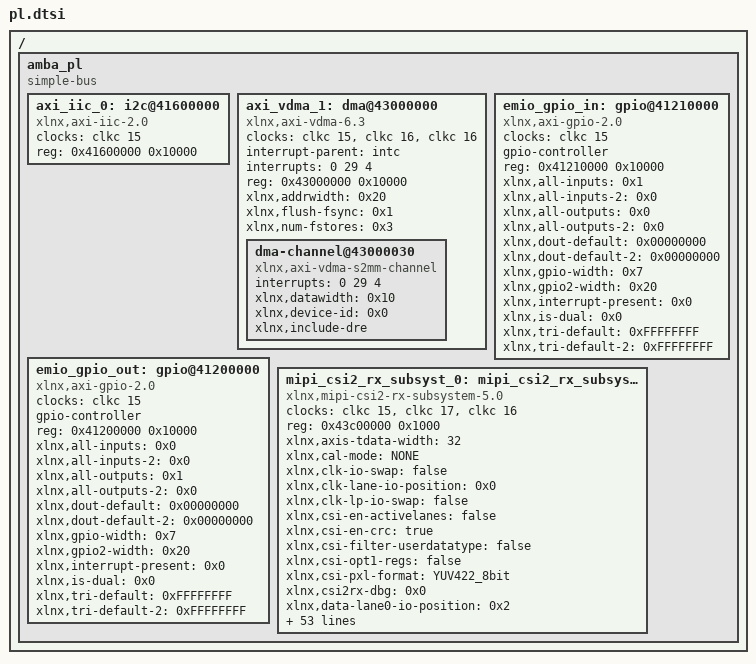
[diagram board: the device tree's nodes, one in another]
/*
 * CAUTION: This file is automatically generated by Xilinx.
 * Version:  
 * Today is: Sat Nov 14 14:24:52 2020
 */


/ {
	amba_pl: amba_pl {
		#address-cells = <1>;
		#size-cells = <1>;
		compatible = "simple-bus";
		ranges ;
		axi_iic_0: i2c@41600000 {
			#address-cells = <1>;
			#size-cells = <0>;
			clock-names = "s_axi_aclk";
			clocks = <&clkc 15>;
			compatible = "xlnx,axi-iic-2.0", "xlnx,xps-iic-2.00.a";
			reg = <0x41600000 0x10000>;
		};
		axi_vdma_1: dma@43000000 {
			#dma-cells = <1>;
			clock-names = "s_axi_lite_aclk", "m_axi_s2mm_aclk", "s_axis_s2mm_aclk";
			clocks = <&clkc 15>, <&clkc 16>, <&clkc 16>;
			compatible = "xlnx,axi-vdma-6.3", "xlnx,axi-vdma-1.00.a";
			interrupt-names = "s2mm_introut";
			interrupt-parent = <&intc>;
			interrupts = <0 29 4>;
			reg = <0x43000000 0x10000>;
			xlnx,addrwidth = <0x20>;
			xlnx,flush-fsync = <0x1>;
			xlnx,num-fstores = <0x3>;
			dma-channel@43000030 {
				compatible = "xlnx,axi-vdma-s2mm-channel";
				interrupts = <0 29 4>;
				xlnx,datawidth = <0x10>;
				xlnx,device-id = <0x0>;
				xlnx,include-dre ;
			};
		};
		emio_gpio_in: gpio@41210000 {
			#gpio-cells = <3>;
			clock-names = "s_axi_aclk";
			clocks = <&clkc 15>;
			compatible = "xlnx,axi-gpio-2.0", "xlnx,xps-gpio-1.00.a";
			gpio-controller ;
			reg = <0x41210000 0x10000>;
			xlnx,all-inputs = <0x1>;
			xlnx,all-inputs-2 = <0x0>;
			xlnx,all-outputs = <0x0>;
			xlnx,all-outputs-2 = <0x0>;
			xlnx,dout-default = <0x00000000>;
			xlnx,dout-default-2 = <0x00000000>;
			xlnx,gpio-width = <0x7>;
			xlnx,gpio2-width = <0x20>;
			xlnx,interrupt-present = <0x0>;
			xlnx,is-dual = <0x0>;
			xlnx,tri-default = <0xFFFFFFFF>;
			xlnx,tri-default-2 = <0xFFFFFFFF>;
		};
		emio_gpio_out: gpio@41200000 {
			#gpio-cells = <3>;
			clock-names = "s_axi_aclk";
			clocks = <&clkc 15>;
			compatible = "xlnx,axi-gpio-2.0", "xlnx,xps-gpio-1.00.a";
			gpio-controller ;
			reg = <0x41200000 0x10000>;
			xlnx,all-inputs = <0x0>;
			xlnx,all-inputs-2 = <0x0>;
			xlnx,all-outputs = <0x1>;
			xlnx,all-outputs-2 = <0x0>;
			xlnx,dout-default = <0x00000000>;
			xlnx,dout-default-2 = <0x00000000>;
			xlnx,gpio-width = <0x7>;
			xlnx,gpio2-width = <0x20>;
			xlnx,interrupt-present = <0x0>;
			xlnx,is-dual = <0x0>;
			xlnx,tri-default = <0xFFFFFFFF>;
			xlnx,tri-default-2 = <0xFFFFFFFF>;
		};
		mipi_csi2_rx_subsyst_0: mipi_csi2_rx_subsystem@43c00000 {
			clock-names = "lite_aclk", "dphy_clk_200M", "video_aclk";
			clocks = <&clkc 15>, <&clkc 17>, <&clkc 16>;
			compatible = "xlnx,mipi-csi2-rx-subsystem-5.0";
			reg = <0x43c00000 0x1000>;
			xlnx,axis-tdata-width = <32>;
			xlnx,cal-mode = "NONE";
			xlnx,clk-io-swap = "false";
			xlnx,clk-lane-io-position = <0x0>;
			xlnx,clk-lp-io-swap = "false";
			xlnx,csi-en-activelanes = "false";
			xlnx,csi-en-crc = "true";
			xlnx,csi-filter-userdatatype = "false";
			xlnx,csi-opt1-regs = "false";
			xlnx,csi-pxl-format = "YUV422_8bit";
			xlnx,csi2rx-dbg = <0x0>;
			xlnx,data-lane0-io-position = <0x2>;
			xlnx,data-lane1-io-position = <0x4>;
			xlnx,data-lane2-io-position = <0x6>;
			xlnx,data-lane3-io-position = <0x8>;
			xlnx,dl0-io-swap = "false";
			xlnx,dl0-lp-io-swap = "false";
			xlnx,dl1-io-swap = "false";
			xlnx,dl1-lp-io-swap = "false";
			xlnx,dl2-io-swap = "false";
			xlnx,dl2-lp-io-swap = "false";
			xlnx,dl3-io-swap = "false";
			xlnx,dl3-lp-io-swap = "false";
			xlnx,dphy-lanes = <0x4>;
			xlnx,dphy-mode = "SLAVE";
			xlnx,en-bg0-pin0 = "false";
			xlnx,en-bg0-pin6 = "false";
			xlnx,en-bg1-pin0 = "false";
			xlnx,en-bg1-pin6 = "false";
			xlnx,en-bg2-pin0 = "false";
			xlnx,en-bg2-pin6 = "false";
			xlnx,en-bg3-pin0 = "false";
			xlnx,en-bg3-pin6 = "false";
			xlnx,en-clk300m = "false";
			xlnx,en-cnts-byte-clk = "false";
			xlnx,en-csi-v2-0 = "false";
			xlnx,en-exdesigns = "false";
			xlnx,en-timeout-regs = "false";
			xlnx,en-vcx = "false";
			xlnx,esc-timeout = <0x6400>;
			xlnx,exdes-board = "ZCU102";
			xlnx,exdes-config = "MIPI_Video_Pipe_Camera_to_Display";
			xlnx,exdes-fmc = "LI-IMX274MIPI-FMC V1.0 Single Sensor";
			xlnx,fifo-rd-en-control = "true";
			xlnx,hs-line-rate = <0x320>;
			xlnx,hs-settle-ns = <0x93>;
			xlnx,hs-timeout = <0x10005>;
			xlnx,idly-group-name = "mipi_csi2rx_idly_group";
			xlnx,idly-tap = <0x1>;
			xlnx,init = <0x186a0>;
			xlnx,is-7series = "true";
			xlnx,is-versal = "false";
			xlnx,lprx-disable-extport = <0x0>;
			xlnx,max-lanes = <4>;
			xlnx,mipi-slv-int = <0x0>;
			xlnx,ooc-vid-clk = "6.666";
			xlnx,ppc = <1>;
			xlnx,rcve-alt-deskew-seq = "false";
			xlnx,rcve-deskew-seq = "false";
			xlnx,share-idlyctrl = "false";
			xlnx,stretch-line-rate = <0xdac>;
			xlnx,vc = <4>;
			xlnx,vfb ;
		};
	};
};
